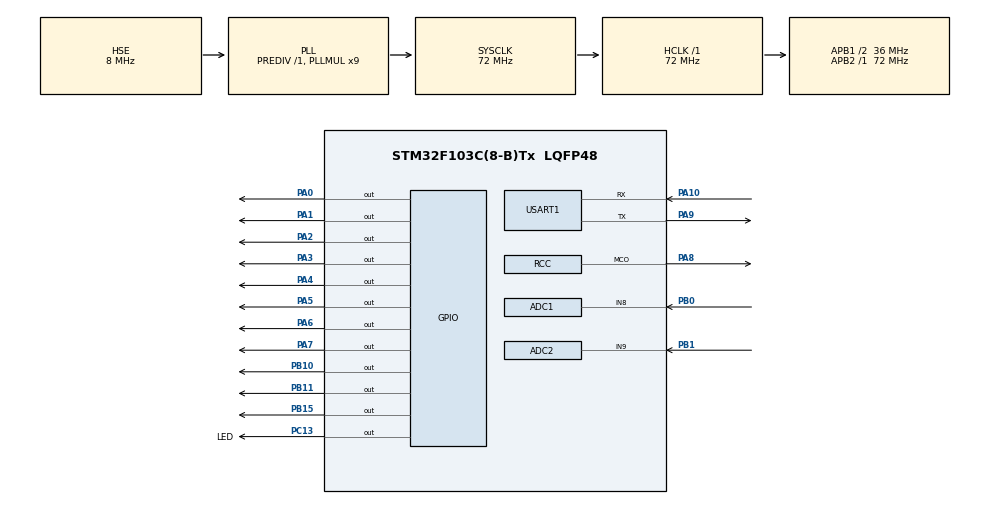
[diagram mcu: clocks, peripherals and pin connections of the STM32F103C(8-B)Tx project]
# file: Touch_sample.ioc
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ADC1.Channel-0\#ChannelRegularConversion=ADC_CHANNEL_8
ADC1.NbrOfConversionFlag=1
ADC1.Rank-0\#ChannelRegularConversion=1
ADC1.SamplingTime-0\#ChannelRegularConversion=ADC_SAMPLETIME_71CYCLES_5
ADC1.master=1
ADC2.Channel-4\#ChannelRegularConversion=ADC_CHANNEL_9
ADC2.NbrOfConversionFlag=1
ADC2.Rank-4\#ChannelRegularConversion=1
ADC2.SamplingTime-4\#ChannelRegularConversion=ADC_SAMPLETIME_71CYCLES_5
Mcu.Family=STM32F1
Mcu.Name=STM32F103C(8-B)Tx
Mcu.Package=LQFP48
NVIC.PriorityGroup=NVIC_PRIORITYGROUP_4
NVIC.TIM3_IRQn=true\:1\:0\:true\:false\:true
PA0-WKUP.GPIO_Speed=GPIO_SPEED_FREQ_HIGH
PA0-WKUP.Signal=GPIO_Output
PA1.GPIO_Speed=GPIO_SPEED_FREQ_HIGH
PA1.Signal=GPIO_Output
PA10.Mode=Asynchronous
PA10.Signal=USART1_RX
PA13.Mode=Serial_Wire
PA13.Signal=SYS_JTMS-SWDIO
PA14.Mode=Serial_Wire
PA14.Signal=SYS_JTCK-SWCLK
PA2.GPIO_Speed=GPIO_SPEED_FREQ_HIGH
PA2.Signal=GPIO_Output
PA3.GPIO_Speed=GPIO_SPEED_FREQ_HIGH
PA3.Signal=GPIO_Output
PA4.Signal=GPIO_Output
PA5.GPIO_Speed=GPIO_SPEED_FREQ_HIGH
PA5.Signal=GPIO_Output
PA6.GPIO_Speed=GPIO_SPEED_FREQ_HIGH
PA6.Signal=GPIO_Output
PA7.GPIO_Speed=GPIO_SPEED_FREQ_HIGH
PA7.Signal=GPIO_Output
PA8.GPIO_Speed=GPIO_SPEED_FREQ_HIGH
PA8.Mode=Clock-out
PA8.Signal=RCC_MCO
PA9.Mode=Asynchronous
PA9.Signal=USART1_TX
PB0.Signal=ADCx_IN8
PB1.Signal=ADCx_IN9
PB10.Signal=GPIO_Output
PB11.Signal=GPIO_Output
PB15.Signal=GPIO_Output
PC13-TAMPER-RTC.GPIO_Label=LED
PC13-TAMPER-RTC.Signal=GPIO_Output
PD0-OSC_IN.Mode=HSE-External-Oscillator
PD0-OSC_IN.Signal=RCC_OSC_IN
PD1-OSC_OUT.Mode=HSE-External-Oscillator
PD1-OSC_OUT.Signal=RCC_OSC_OUT
ProjectManager.HeapSize=0x200
ProjectManager.StackSize=0x400
ProjectManager.TargetToolchain=Other Toolchains (GPDSC)
RCC.ADCPresc=RCC_ADCPCLK2_DIV6
RCC.AHBFreq_Value=72000000
RCC.APB1CLKDivider=RCC_HCLK_DIV2
RCC.APB1Freq_Value=36000000
RCC.APB1TimFreq_Value=72000000
RCC.APB2Freq_Value=72000000
RCC.APB2TimFreq_Value=72000000
RCC.HCLKFreq_Value=72000000
RCC.HSIState=RCC_HSI_ON
RCC.PLLMUL=RCC_PLL_MUL9
RCC.PLLSourceVirtual=RCC_PLLSOURCE_HSE
RCC.RCC_MCOSource=RCC_MCO1SOURCE_PLLCLK
RCC.SYSCLKFreq_VALUE=72000000
RCC.SYSCLKSource=RCC_SYSCLKSOURCE_PLLCLK
RCC.USBFreq_Value=72000000
SH.ADCx_IN8.0=ADC1_IN8,IN8
SH.ADCx_IN9.0=ADC2_IN9,IN9
TIM3.Period=2499
TIM3.Prescaler=3199
VP_CRC_VS_CRC.Mode=CRC_Activate
VP_TIM3_VS_ClockSourceINT.Mode=Internal
board=Touch_sample

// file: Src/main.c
/**
  ******************************************************************************
  * File Name          : main.c
  * Description        : Main program body
  ******************************************************************************
  *
  * COPYRIGHT(c) 2017 STMicroelectronics
  *
  * Redistribution and use in source and binary forms, with or without modification,
  * are permitted provided that the following conditions are met:
  *   1. Redistributions of source code must retain the above copyright notice,
  *      this list of conditions and the following disclaimer.
  *   2. Redistributions in binary form must reproduce the above copyright notice,
  *      this list of conditions and the following disclaimer in the documentation
  *      and/or other materials provided with the distribution.
  *   3. Neither the name of STMicroelectronics nor the names of its contributors
  *      may be used to endorse or promote products derived from this software
  *      without specific prior written permission.
  *
  * THIS SOFTWARE IS PROVIDED BY THE COPYRIGHT HOLDERS AND CONTRIBUTORS "AS IS"
  * AND ANY EXPRESS OR IMPLIED WARRANTIES, INCLUDING, BUT NOT LIMITED TO, THE
  * IMPLIED WARRANTIES OF MERCHANTABILITY AND FITNESS FOR A PARTICULAR PURPOSE ARE
  * DISCLAIMED. IN NO EVENT SHALL THE COPYRIGHT HOLDER OR CONTRIBUTORS BE LIABLE
  * FOR ANY DIRECT, INDIRECT, INCIDENTAL, SPECIAL, EXEMPLARY, OR CONSEQUENTIAL
  * DAMAGES (INCLUDING, BUT NOT LIMITED TO, PROCUREMENT OF SUBSTITUTE GOODS OR
  * SERVICES; LOSS OF USE, DATA, OR PROFITS; OR BUSINESS INTERRUPTION) HOWEVER
  * CAUSED AND ON ANY THEORY OF LIABILITY, WHETHER IN CONTRACT, STRICT LIABILITY,
  * OR TORT (INCLUDING NEGLIGENCE OR OTHERWISE) ARISING IN ANY WAY OUT OF THE USE
  * OF THIS SOFTWARE, EVEN IF ADVISED OF THE POSSIBILITY OF SUCH DAMAGE.
  *
  ******************************************************************************
  */
#include "main.h"
#include "board_config.h"
#include "stm32f1xx_hal.h"
#ifdef USING_TOUCH_ADC
#include "adc.h"
#endif
#include "crc.h"
#include "tim.h"
#include "usart.h"
#include "gpio.h"

/* USER CODE BEGIN Includes */
#include "board_config.h"
#include "Touch_sample.h"
#include "Board_Touch.h"
#include "LCDConf_F103_24.h"
#include <string.h>
/* USER CODE END Includes */

/* USER CODE BEGIN PV */
/* Private variables ---------------------------------------------------------*/

/* USER CODE END PV */

void SystemClock_Config(void);
void Error_Handler(void);

/* USER CODE BEGIN PFP */
/* Private function prototypes -----------------------------------------------*/

/* USER CODE END PFP */

/* USER CODE BEGIN 0 */

void serialTrace(unsigned char * message)
{
	HAL_UART_Transmit(&huart1, message, strlen((char*)message), 1000);
}

/*void GUI_is_initialized(void){
	char szLcdID[10];
	sprintf(szLcdID, "ID: %0x4\n\r", tftID);
serialTrace(szLcdID);
}
*/
/* USER CODE END 0 */

int main(void)
{

  /* USER CODE BEGIN 1 */
	CoreDebug->DEMCR |= CoreDebug_DEMCR_TRCENA_Msk;
	DWT->CYCCNT = 0;
  /* Enable hi resolution counter */
	DWT->CTRL &= ~0x00000001;
	DWT->CTRL |= 0x00000001;
  /* USER CODE END 1 */

  /* MCU Configuration----------------------------------------------------------*/

  /* Reset of all peripherals, Initializes the Flash interface and the Systick. */
  HAL_Init();

  /* Configure the system clock */
  SystemClock_Config();

  /* Initialize all configured peripherals */
  MX_GPIO_Init();
  MX_TIM3_Init();
  MX_USART1_UART_Init();
#ifdef USING_TOUCH_ADC
 MX_ADC1_Init();
 MX_ADC2_Init();
#endif
  MX_CRC_Init();

  /* USER CODE BEGIN 2 */
	HAL_UART_Transmit(&huart1, "begin\n\r", 7, 1000);
	MainTask();
  /* USER CODE END 2 */

  /* Infinite loop */
  while (1)
  {

  }

}

/** System Clock Configuration
*/
void SystemClock_Config(void)
{

  RCC_OscInitTypeDef RCC_OscInitStruct;
  RCC_ClkInitTypeDef RCC_ClkInitStruct;
  RCC_PeriphCLKInitTypeDef PeriphClkInit;

    /**Initializes the CPU, AHB and APB busses clocks
    */
  RCC_OscInitStruct.OscillatorType = RCC_OSCILLATORTYPE_HSE;
  RCC_OscInitStruct.HSEState = RCC_HSE_ON;
  RCC_OscInitStruct.HSEPredivValue = RCC_HSE_PREDIV_DIV1;
  RCC_OscInitStruct.HSIState = RCC_HSI_ON;
  RCC_OscInitStruct.PLL.PLLState = RCC_PLL_ON;

  RCC_OscInitStruct.PLL.PLLSource = RCC_PLLSOURCE_HSE;
  RCC_OscInitStruct.PLL.PLLMUL = RCC_PLL_MUL9;
  if (HAL_RCC_OscConfig(&RCC_OscInitStruct) != HAL_OK)
  {
    Error_Handler();
  }

    /**Initializes the CPU, AHB and APB busses clocks
    */
  RCC_ClkInitStruct.ClockType = RCC_CLOCKTYPE_HCLK|RCC_CLOCKTYPE_SYSCLK
                              |RCC_CLOCKTYPE_PCLK1|RCC_CLOCKTYPE_PCLK2;
  RCC_ClkInitStruct.SYSCLKSource = RCC_SYSCLKSOURCE_PLLCLK;
  RCC_ClkInitStruct.AHBCLKDivider = RCC_SYSCLK_DIV1;
  RCC_ClkInitStruct.APB1CLKDivider = RCC_HCLK_DIV2;
  RCC_ClkInitStruct.APB2CLKDivider = RCC_HCLK_DIV1;

  if (HAL_RCC_ClockConfig(&RCC_ClkInitStruct, FLASH_LATENCY_2) != HAL_OK)
  {
    Error_Handler();
  }

  PeriphClkInit.PeriphClockSelection = RCC_PERIPHCLK_ADC;
  PeriphClkInit.AdcClockSelection = RCC_ADCPCLK2_DIV6;
  if (HAL_RCCEx_PeriphCLKConfig(&PeriphClkInit) != HAL_OK)
  {
    Error_Handler();
  }

  HAL_RCC_MCOConfig(RCC_MCO, RCC_MCO1SOURCE_PLLCLK, RCC_MCODIV_1);

    /**Configure the Systick interrupt time
    */
  HAL_SYSTICK_Config(HAL_RCC_GetHCLKFreq()/1000);

    /**Configure the Systick
    */
  HAL_SYSTICK_CLKSourceConfig(SYSTICK_CLKSOURCE_HCLK);

  /* SysTick_IRQn interrupt configuration */
  HAL_NVIC_SetPriority(SysTick_IRQn, 0, 0);
}

void Error_Handler(void)
{
  while(1)
  {
  }
}

/************************ (C) COPYRIGHT STMicroelectronics *****END OF FILE****/
